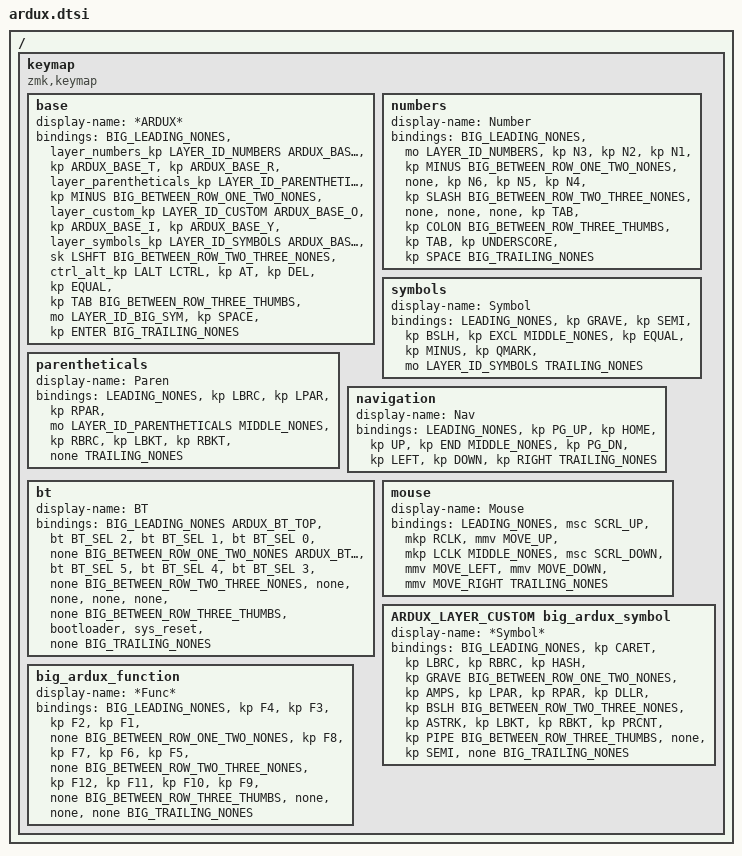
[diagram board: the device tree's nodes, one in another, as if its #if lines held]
/*
 * Copyright (c) 2021 Mike "KemoNine" Crosson
 *
 * SPDX-License-Identifier: MIT
 */

#include "combos.dtsi"

/*****************************************
 * ARDUX website : https://www.ardux.io
 * Primary reference : https://www.ardux.io/_FILES/images/ARDUX.jpg
*****************************************/

/*****************************************
 * Setting up ARDUX comboing
 *   - Enabled right OR left handed orientation
 *   - Please note: A/E key positions should be on your INDEX finger
 *     - The online reference is for right handed use
 *     - When using the ARDUX layout left handed you'll want to ensure your keypositions are flipped along the Y axis
 *   - Update/adjust the key positions using your boards keymap 
 *     - See below for additional details
 *   - YOU MUST SET THE FOLLOWING CONFIG VALUES FOR THIS SETUP TO WORK PROPERLY IN YOUR BOARDS .conf FILE
 *     - CONFIG_ZMK_COMBO_MAX_COMBOS_PER_KEY=24
 *     - CONFIG_ZMK_COMBO_MAX_KEYS_PER_COMBO=8
 *     - CONFIG_ZMK_COMBO_MAX_PRESSED_COMBOS=8
 *****************************************/

/*****************************************
 * Define which layout you want to use
 *  ONLY ENABLE ONE OF THESE
*****************************************/
//#define ARDUX_RIGHT 1
//#define ARDUX_LEFT 1
//#define ARDUX_BIG 1
// If you use COLEMAK as your standard keyboard layout, you may want this
//     This define will make base ardux keys and N more in line with COLEMAK
//#define ARDUX_COLEMAK 1

/*****************************************
 * Define key positions used for combos
 * These definitions are used to define the various ARDUX combos
 * 
 * Please see the documentation on "combos" for details on how to find the proper key positions
 *
 * Default key positions are for a generic 4x2 keyboard and should NOT be used outright
 * DEFINE these definitions in your boards keymap BEFORE including ardux.dtsi
*****************************************/
// ARTS Row
// #define KEY_A 0
// #define KEY_R 1
// #define KEY_T 2
// #define KEY_S 3
// EYIO Row
// #define KEY_E 4
// #define KEY_Y 5
// #define KEY_I 6
// #define KEY_O 7
// Big ardux F1-12 layer keys for combo
// #define KEY_F_TOP -1
// #define KEY_F_BOTTOM -1

/*****************************************
 * Define key position offsets in main keymap
 *
 * In order to make this keymap flexible, you must setup the number of &none "offsets" to use
 * The defines below should be set in your LOCAL keymap and using the above "NONE([hundreds],[tens],[ones])" macro for filling in the gaps
*****************************************/
// #define LEADING_NONES NONE(0, 1, 0)
// #define MIDDLE_NONES NONE(0, 0, 3)
// #define TRAILING_NONES NONE(0, 1, 0)
// #define BIG_LEADING_NONES NONE(0, 0, 0)
// #define BIG_BETWEEN_ROW_ONE_TWO_NONES NONE(0, 0, 0)
// #define BIG_BETWEEN_ROW_TWO_THREE_NONES NONE(0, 0, 0)
// #define BIG_BETWEEN_ROW_THREE_THUMBS NONE(0, 0, 0)
// #define BIG_TRAILING_NONES NONE(0, 0, 0)


/*****************************************
 * Define custom layer
 *
 * You can override this layer by copy/pasting the into your keymap *before* including the ardux.dtsi file
 * Once added to your keymap you can adjust as you see fit
*****************************************/
#if !defined ARDUX_LAYER_CUSTOM
#if defined ARDUX_RIGHT
#define ARDUX_LAYER_CUSTOM                                            \
		custom {                                                       \
			display-name = "Custom";                                          \
			bindings = <                                               \
				LEADING_NONES                                          \
				&kp C_MUTE &kp INS   &kp C_VOL_UP  &none               \
				MIDDLE_NONES                                           \
				&sk RSHFT  &kp PSCRN &kp C_VOL_DN  &mo LAYER_ID_CUSTOM \
				TRAILING_NONES                                         \
			>;                                                         \
		};
#endif
#if defined ARDUX_LEFT
#define ARDUX_LAYER_CUSTOM                                            \
		custom {                                                       \
			display-name = "Custom";                                          \
			bindings = <                                               \
				LEADING_NONES                                          \
				&none               &kp C_VOL_UP  &kp INS   &kp C_MUTE \
				MIDDLE_NONES                                           \
				&mo LAYER_ID_CUSTOM &kp C_VOL_DN  &kp PSCRN &sk RSHFT  \
				TRAILING_NONES                                         \
			>;                                                         \
		};
#endif
#endif

/*****************************************
 * Standard ARDUX layer definitions
 * !!!!!!!!!! FOR RIGHT HANDED USE !!!!!!!!!!
 *****************************************/
#if defined ARDUX_RIGHT
/ {
	keymap {
		compatible = "zmk,keymap";
		#if defined ARDUX_BIG
		base {
			display-name = "*ARDUX*";
			bindings = <
				BIG_LEADING_NONES
				&kp MINUS            &layer_parentheticals_kp LAYER_ID_PARENTHETICALS ARDUX_BASE_A    &kp ARDUX_BASE_R     &kp ARDUX_BASE_T     &layer_numbers_kp LAYER_ID_NUMBERS ARDUX_BASE_S
				BIG_BETWEEN_ROW_ONE_TWO_NONES
				&sk LSHFT            &layer_symbols_kp LAYER_ID_SYMBOLS ARDUX_BASE_E                  &kp ARDUX_BASE_Y     &kp ARDUX_BASE_I     &layer_custom_kp LAYER_ID_CUSTOM ARDUX_BASE_O
				BIG_BETWEEN_ROW_TWO_THREE_NONES
				&kp TAB              &kp EQUAL                                                         &kp DEL               &kp AT                &ctrl_alt_kp LALT LCTRL
				BIG_BETWEEN_ROW_THREE_THUMBS
				&kp ENTER            &kp SPACE                                                         &mo LAYER_ID_BIG_SYM
				BIG_TRAILING_NONES
			>;
		};
		#else
		base {
			display-name = "ARDUX";
			bindings = <
				LEADING_NONES
				&layer_parentheticals_kp LAYER_ID_PARENTHETICALS ARDUX_BASE_A  &kp ARDUX_BASE_R     &kp ARDUX_BASE_T     &layer_numbers_kp LAYER_ID_NUMBERS ARDUX_BASE_S
				MIDDLE_NONES
				&layer_symbols_kp LAYER_ID_SYMBOLS ARDUX_BASE_E                &kp ARDUX_BASE_Y     &kp ARDUX_BASE_I     &layer_custom_kp LAYER_ID_CUSTOM ARDUX_BASE_O
				TRAILING_NONES
				#if defined CUSTOM_THUMB
				CUSTOM_THUMB
				#endif
			>;
		};
		#endif
		#if defined ARDUX_BIG
		numbers {
			display-name = "Number";
			bindings = <
				BIG_LEADING_NONES
				&kp MINUS &kp N1 &kp N2 &kp N3 &mo LAYER_ID_NUMBERS
				BIG_BETWEEN_ROW_ONE_TWO_NONES
				&kp SLASH &kp N4 &kp N5 &kp N6 &none
				BIG_BETWEEN_ROW_TWO_THREE_NONES
				&kp COLON &kp TAB &none &none &none
				BIG_BETWEEN_ROW_THREE_THUMBS
				&kp SPACE &kp UNDERSCORE &kp TAB
				BIG_TRAILING_NONES
			>;
		};
		#else
		numbers {
			display-name = "Number";
			bindings = <
				LEADING_NONES
				&kp N1                                              &kp N2    &kp N3    &mo LAYER_ID_NUMBERS
				MIDDLE_NONES
				&kp N4                                              &kp N5    &kp N6    &none
				TRAILING_NONES
			>;
		};
		#endif
		symbols {
			display-name = "Symbol";
			bindings = <
				LEADING_NONES
				&kp EXCL                                            &kp BSLH  &kp SEMI  &kp GRAVE
				MIDDLE_NONES
				&mo LAYER_ID_SYMBOLS                                &kp QMARK &kp MINUS &kp EQUAL
				TRAILING_NONES
			>;
		};
		parentheticals {
			display-name = "Paren";
			bindings = <
				LEADING_NONES
				&mo LAYER_ID_PARENTHETICALS                         &kp LPAR  &kp RPAR  &kp LBRC
				MIDDLE_NONES
				&none                                               &kp LBKT  &kp RBKT  &kp RBRC
				TRAILING_NONES
			>;
		};
		navigation {
			display-name = "Nav";
			bindings = <
				LEADING_NONES
				&kp HOME                                            &kp UP    &kp END   &kp PG_UP
				MIDDLE_NONES
				&kp LEFT                                            &kp DOWN  &kp RIGHT &kp PG_DN
				TRAILING_NONES
			>;
		};
		#if defined ARDUX_BIG
		bt {
			display-name = "BT";
			bindings = <
				BIG_LEADING_NONES
				&none &bt BT_SEL 0 &bt BT_SEL 1 &bt BT_SEL 2 ARDUX_BT_TOP
				BIG_BETWEEN_ROW_ONE_TWO_NONES
				&none &bt BT_SEL 3 &bt BT_SEL 4 &bt BT_SEL 5 ARDUX_BT_BOTTOM
				BIG_BETWEEN_ROW_TWO_THREE_NONES
				&none &none &none &none &none
				BIG_BETWEEN_ROW_THREE_THUMBS
				&none &sys_reset &bootloader
				BIG_TRAILING_NONES
			>;
		};
		#else
		bt {
			display-name = "BT";
			bindings = <
				LEADING_NONES
				&bt BT_SEL 0 &bt BT_SEL 1 &bt BT_SEL 2 ARDUX_BT_TOP
				MIDDLE_NONES
				&bt BT_SEL 3 &bt BT_SEL 4 &bt BT_SEL 5 ARDUX_BT_BOTTOM
				TRAILING_NONES
			>;
		};
		#endif
		mouse {
			display-name = "Mouse";
			bindings = <
				LEADING_NONES
				&mkp LCLK                                        &mmv MOVE_UP    &mkp RCLK        &msc SCRL_UP
				MIDDLE_NONES
				&mmv MOVE_LEFT                                   &mmv MOVE_DOWN  &mmv MOVE_RIGHT  &msc SCRL_DOWN
				TRAILING_NONES
			>;
		};
		ARDUX_LAYER_CUSTOM
		#if defined ARDUX_BIG
		big_ardux_symbol {
			display-name = "*Symbol*";
			bindings = <
				BIG_LEADING_NONES
				&kp GRAVE &kp HASH  &kp LBRC &kp RBRC &kp CARET
				BIG_BETWEEN_ROW_ONE_TWO_NONES
				&kp BSLH  &kp DLLR  &kp LPAR &kp RPAR &kp AMPS
				BIG_BETWEEN_ROW_TWO_THREE_NONES
				&kp PIPE  &kp PRCNT &kp LBKT &kp RBKT &kp ASTRK
				BIG_BETWEEN_ROW_THREE_THUMBS
				&trans    &kp SEMI  &none
				BIG_TRAILING_NONES
			>;
		};
		big_ardux_function {
			display-name = "*Func*";
			bindings = <
				BIG_LEADING_NONES
				&none  &kp F1 &kp F2  &kp F3  &kp F4
				BIG_BETWEEN_ROW_ONE_TWO_NONES
				&none  &kp F5 &kp F6  &kp F7  &kp F8
				BIG_BETWEEN_ROW_TWO_THREE_NONES
				&none  &kp F9 &kp F10 &kp F11 &kp F12
				BIG_BETWEEN_ROW_THREE_THUMBS
				&trans &none   &none
				BIG_TRAILING_NONES
			>;
		};
		#endif
	};
};
#endif

/*****************************************
 * Standard ARDUX layer definitions
 * !!!!!!!!!! FOR LEFT HANDED USE !!!!!!!!!!
 *****************************************/
#if defined ARDUX_LEFT
/ {
	keymap {
		compatible = "zmk,keymap";
		#if defined ARDUX_BIG
		base {
			display-name = "*ARDUX*";
			bindings = <
				BIG_LEADING_NONES
				&layer_numbers_kp LAYER_ID_NUMBERS ARDUX_BASE_S    &kp ARDUX_BASE_T     &kp ARDUX_BASE_R     &layer_parentheticals_kp LAYER_ID_PARENTHETICALS ARDUX_BASE_A &kp MINUS
				BIG_BETWEEN_ROW_ONE_TWO_NONES
				&layer_custom_kp LAYER_ID_CUSTOM ARDUX_BASE_O      &kp ARDUX_BASE_I     &kp ARDUX_BASE_Y     &layer_symbols_kp LAYER_ID_SYMBOLS ARDUX_BASE_E               &sk LSHFT
				BIG_BETWEEN_ROW_TWO_THREE_NONES
				&ctrl_alt_kp LALT LCTRL                             &kp AT                &kp DEL               &kp EQUAL                                                      &kp TAB
				BIG_BETWEEN_ROW_THREE_THUMBS
				&mo LAYER_ID_BIG_SYM                                &kp SPACE             &kp ENTER
				BIG_TRAILING_NONES
			>;
		};
		#else
		base {
			display-name = "ARDUX";
			bindings = <
				LEADING_NONES
				&layer_numbers_kp LAYER_ID_NUMBERS ARDUX_BASE_S        &kp ARDUX_BASE_T     &kp ARDUX_BASE_R     &layer_parentheticals_kp LAYER_ID_PARENTHETICALS ARDUX_BASE_A
				MIDDLE_NONES
				&layer_custom_kp LAYER_ID_CUSTOM ARDUX_BASE_O          &kp ARDUX_BASE_I     &kp ARDUX_BASE_Y     &layer_symbols_kp LAYER_ID_SYMBOLS ARDUX_BASE_E
				TRAILING_NONES
				#if defined CUSTOM_THUMB
				CUSTOM_THUMB
				#endif
			>;
		};
		#endif
		#if defined ARDUX_BIG
		numbers {
			display-name = "Number";
			bindings = <
				BIG_LEADING_NONES
				&mo LAYER_ID_NUMBERS &kp N3 &kp N2 &kp N1 &kp MINUS
				BIG_BETWEEN_ROW_ONE_TWO_NONES
				&none &kp N6 &kp N5 &kp N4 &kp SLASH
				BIG_BETWEEN_ROW_TWO_THREE_NONES
				&none &none &none &kp TAB &kp COLON
				BIG_BETWEEN_ROW_THREE_THUMBS
				&kp TAB &kp UNDERSCORE &kp SPACE
				BIG_TRAILING_NONES
			>;
		};
		#else
		numbers {
			display-name = "Number";
			bindings = <
				LEADING_NONES
				&mo LAYER_ID_NUMBERS                        &kp N3    &kp N2    &kp N1
				MIDDLE_NONES
				&none                                       &kp N6    &kp N5    &kp N4
				TRAILING_NONES
			>;
		};
		#endif
		symbols {
			display-name = "Symbol";
			bindings = <
				LEADING_NONES
				&kp GRAVE                                   &kp SEMI  &kp BSLH  &kp EXCL
				MIDDLE_NONES
				&kp EQUAL                                   &kp MINUS &kp QMARK &mo LAYER_ID_SYMBOLS
				TRAILING_NONES
			>;
		};
		parentheticals {
			display-name = "Paren";
			bindings = <
				LEADING_NONES
				&kp LBRC                                    &kp LPAR  &kp RPAR  &mo LAYER_ID_PARENTHETICALS
				MIDDLE_NONES
				&kp RBRC                                    &kp LBKT  &kp RBKT  &none
				TRAILING_NONES
			>;
		};
		navigation {
			display-name = "Nav";
			bindings = <
				LEADING_NONES
				&kp PG_UP                                   &kp HOME  &kp UP    &kp END
				MIDDLE_NONES
				&kp PG_DN                                   &kp LEFT  &kp DOWN  &kp RIGHT
				TRAILING_NONES
			>;
		};
		#if defined ARDUX_BIG
		bt {
			display-name = "BT";
			bindings = <
				BIG_LEADING_NONES
				ARDUX_BT_TOP    &bt BT_SEL 2 &bt BT_SEL 1 &bt BT_SEL 0 &none
				BIG_BETWEEN_ROW_ONE_TWO_NONES
				ARDUX_BT_BOTTOM &bt BT_SEL 5 &bt BT_SEL 4 &bt BT_SEL 3 &none
				BIG_BETWEEN_ROW_TWO_THREE_NONES
				&none &none &none &none &none
				BIG_BETWEEN_ROW_THREE_THUMBS
				&bootloader &sys_reset &none
				BIG_TRAILING_NONES
			>;
		};
		#else
		bt {
			display-name = "BT";
			bindings = <
				LEADING_NONES
				ARDUX_BT_TOP    &bt BT_SEL 2 &bt BT_SEL 1 &bt BT_SEL 0
				MIDDLE_NONES
				ARDUX_BT_BOTTOM &bt BT_SEL 5 &bt BT_SEL 4 &bt BT_SEL 3
				TRAILING_NONES
			>;
		};
		#endif
		mouse {
			display-name = "Mouse";
			bindings = <
				LEADING_NONES
				&msc SCRL_UP                                   &mkp RCLK  &mmv MOVE_UP    &mkp LCLK
				MIDDLE_NONES
				&msc SCRL_DOWN                                   &mmv MOVE_LEFT  &mmv MOVE_DOWN  &mmv MOVE_RIGHT
				TRAILING_NONES
			>;
		};
		ARDUX_LAYER_CUSTOM
		#if defined ARDUX_BIG
		big_ardux_symbol {
			display-name = "*Symbol*";
			bindings = <
				BIG_LEADING_NONES
				&kp CARET &kp LBRC &kp RBRC &kp HASH  &kp GRAVE
				BIG_BETWEEN_ROW_ONE_TWO_NONES
				&kp AMPS  &kp LPAR &kp RPAR &kp DLLR  &kp BSLH
				BIG_BETWEEN_ROW_TWO_THREE_NONES
				&kp ASTRK &kp LBKT &kp RBKT &kp PRCNT &kp PIPE
				BIG_BETWEEN_ROW_THREE_THUMBS
				&none     &kp SEMI &none
				BIG_TRAILING_NONES
			>;
		};
		big_ardux_function {
			display-name = "*Func*";
			bindings = <
				BIG_LEADING_NONES
				&kp F4  &kp F3  &kp F2  &kp F1  &none
				BIG_BETWEEN_ROW_ONE_TWO_NONES
				&kp F8  &kp F7  &kp F6  &kp F5  &none
				BIG_BETWEEN_ROW_TWO_THREE_NONES
				&kp F12 &kp F11 &kp F10 &kp F9 &none
				BIG_BETWEEN_ROW_THREE_THUMBS
				&none   &none   &none
				BIG_TRAILING_NONES
			>;
		};
		#endif
	};
};
#endif
